# D1H.pdf register map
Vendor: Allwinner; Series: D1H.pdf; File version: 0.1
CPU: XuanTie C906 RISC-V CPU 0, little endian, MPU, FPU, double-precision FPU, 0 interrupt priority bits
Registers are 32-bit, read-write, reset 0x0 unless marked. A register's access mark holds for its fields unless they carry their own. Offsets are from the block's base; [hi:lo] are bit positions; {n}, {i} and the like mark numbered series.

## Spinlock
Base 0x03005000
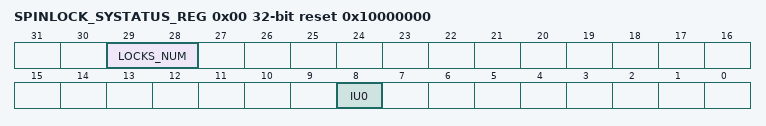
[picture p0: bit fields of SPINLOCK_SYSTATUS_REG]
0x00 SPINLOCK_SYSTATUS_REG reset 0x10000000 — Spinlock System Status Register
  [29:28] LOCKS_NUM ro — Number of lock registers implemented 00: This instance has 256 lock registers 01: This instance has 32 lock registers 10: This instance has 64 lock registers 11: This instance has 128 lock registers
    0=This instance has 256 lock registers; 1=This instance has 32 lock registers; 2=This instance has 64 lock registers; 3=This instance has 128 lock registers
  [8] IU0 ro — In-Use flag0, covering lock register0-31 0: All lock registers 0-31 are in the NotTaken state. 1: At least one of the lock register 0-31 is in the Taken state.
    0=All (All lock registers 0-31 are in the NotTaken state.); 1=At (At least one of the lock register 0-31 is in the Taken state.)
0x10 SPINLOCK_STATUS_REG — Spinlock Status Register
  [31:0] LOCK_REG_STATUS ro — SpinLock[i] status 0: The Spinlock is free 1: The Spinlock is taken
0x20 SPINLOCK_IRQ_EN_REG — Spinlock Interrupt Enable Register
  [31:0] LOCK_IRQ_EN — SpinLock[i] interrupt enable 0: Disable 1: Enable
0x40 SPINLOCK_IRQ_STA_REG — Spinlock Interrupt Status Register
  [31:0] LOCK_IRQ_STATUS write-1-clears — SpinLock[i] interrupt status 0: No effect 1: Pending Writing 1 clears this bit.
{0x80+4i} SPINLOCK_LOCKIN{i}_REG reset not defined (i=0..4)
{0x100+4i} SPINLOCKN_LOCK_REG[{i}] (i=0..31) — SPINLOCKN_LOCK_REG[{i}]
  [0] TAKEN — Lock State Read 0x0: The lock was previously Not Taken (free). The requester is granted the lock. Write 0x0: Set the lock to Not Taken (free). Read 0x1: The lock was previously Taken. The requester is not granted the lock and must retry. Write 0x1: No update to the lock value.

## THS
Base 0x02009400
0x00 THS_CTRL reset 0x1DF002F — THS Control Register
  [31:16] TACQ — ADC acquire time CLK_IN/(n + 1) The default value is 2 us.
0x04 THS_EN — THS Enable Register
  [0] THS_EN — Enable temperature measurement sensor 0: Disable 1: Enable
    0=Disable; 1=Enable
0x08 THS_PER reset 0x3A000 — THS Period Control Register
  [31:12] THERMAL_PER — Temperature measurement period 4096*(n + 1)/CLK_IN The default value is 10 ms.
0x10 THS_DATA_INTC — THS Data Interrupt Control Register
  [0] THS_DATA_IRQ_EN — Enable the interrupt of sensor_data update If enabled, when the measured sensor_data is updated, it will generate an interrupt. 0: Disabled 1: Enabled
    0=Disabled; 1=Enabled
0x14 THS_SHUT_INTC — THS Shut Interrupt Control Register
  [0] SHUT_INT_EN — Enable the shutdown interrupt for the sensor 0: Disabled 1: Enabled
    0=Disabled; 1=Enabled
0x18 THS_ALARM_INTC — THS Alarm Interrupt Control Register
  [0] ALARM_INT_EN — Enable the alarm interrupt for the sensor 0: Disabled 1: Enabled
    0=Disabled; 1=Enabled
0x20 THS_DATA_INTS — THS Data Interrupt Status Register
  [0] THS_DATA_IRQ_STS write-1-clears — Indicates the pending status of the sensor’s data interrupt. Write 1 to clear the pending status. 0: No effect 1: Pending
    0=No_effect; 1=Pending
0x24 THS_SHUT_INTS — THS Shut Interrupt Status Register
  [0] SHUT_INT_STS write-1-clears — Indicates the pending status of the sensor’s shutdown interrupt. Write 1 to clear the pending status. 0: No effect 1: Pending
    0=No_effect; 1=Pending
0x28 THS_ALARM0_INTS
  [0] ALARM_OFF_STS write-1-clears — Alarm interrupt off pending for sensor Write 1 to clear the pending status. 0: No effect 1: Pending
    0=No_effect; 1=Pending
0x2C THS_ALARM_INTS — THS Alarm Interrupt Status Register
  [0] ALARM_INT_STS write-1-clears — Alarm interrupt pending for sensor Write 1 to clear the pending status. 0: No effect 1: Pending
    0=No_effect; 1=Pending
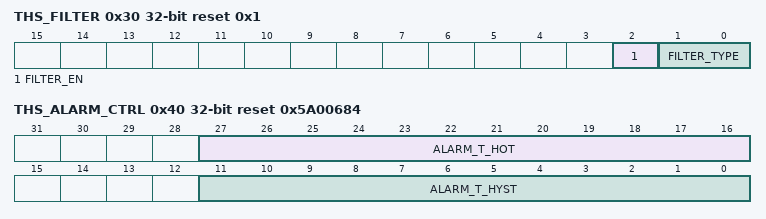
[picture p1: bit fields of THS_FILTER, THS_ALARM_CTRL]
0x30 THS_FILTER reset 0x1 — THS Median Filter Control Register
  [2] FILTER_EN — Filter enable 0: Disabled 1: Enabled
    0=Disabled; 1=Enabled
  [1:0] FILTER_TYPE — Averaging filter type 00: 2 01: 4 10: 8 11: 16
    0=_2; 1=_4; 2=_8; 3=_16
0x40 THS_ALARM_CTRL reset 0x5A00684 — THS Alarm Threshold Control Register
  [27:16] ALARM_T_HOT — Thermal sensor alarm threshold for hot temperature
  [11:0] ALARM_T_HYST — Thermal sensor alarm threshold for hysteresis temperature
0x80 THS_SHUTDOWN_CTRL reset 0x4E9 — THS Shutdown Threshold Control Register
  [11:0] SHUT_T_HOT — Thermal sensor shutdown threshold for hot temperature
0xA0 THS_CDATA reset 0x800 — THS Calibration Data
  [11:0] THS_CDATA — Thermal sensor calibration data
0xC0 THS_DATA
  [11:0] THS_DATA ro — Temperature measurement data of sensor
